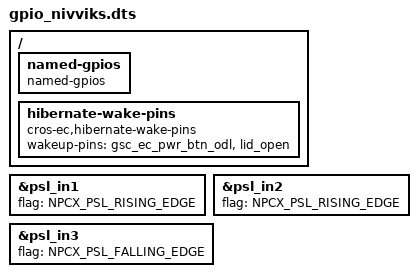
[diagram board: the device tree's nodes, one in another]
/* Copyright 2021 The Chromium OS Authors. All rights reserved.
 * Use of this source code is governed by a BSD-style license that can be
 * found in the LICENSE file.
 */

/ {
	named-gpios {
		compatible = "named-gpios";

#include "nivviks_generated.dts"

	};

	hibernate-wake-pins {
		compatible = "cros-ec,hibernate-wake-pins";
		wakeup-pins = <
			&gsc_ec_pwr_btn_odl
			&lid_open
		>;
	};
};

/* Power switch logic input pads */
/* LID_OPEN_OD */
&psl_in1 {
	flag = <NPCX_PSL_RISING_EDGE>;
};

/* ACOK_EC_OD */
&psl_in2 {
	flag = <NPCX_PSL_RISING_EDGE>;
};

/* GSC_EC_PWR_BTN_ODL */
&psl_in3 {
	flag = <NPCX_PSL_FALLING_EDGE>;
};
